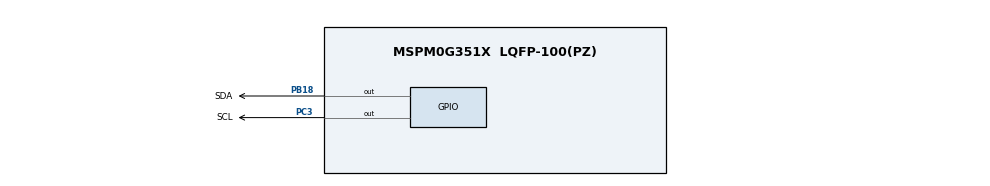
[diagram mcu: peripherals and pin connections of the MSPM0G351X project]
/**
 * @cliArgs --device "MSPM0G351X" --part "Default" --package "LQFP-100(PZ)" --product "mspm0_sdk@2.10.00.04"
 * @versions {"tool":"1.27.0+4565"}
 */

/**
 * Import the modules used in this configuration.
 */
const GPIO    = scripting.addModule("/ti/driverlib/GPIO", {}, false);
const GPIO1   = GPIO.addInstance();
const SYSCTL  = scripting.addModule("/ti/driverlib/SYSCTL");
const SYSTICK = scripting.addModule("/ti/driverlib/SYSTICK");
const UART    = scripting.addModule("/ti/driverlib/UART", {}, false);
const UART1   = UART.addInstance();

/**
 * Write custom configuration values to the imported modules.
 */
const divider9       = system.clockTree["UDIV"];
divider9.divideValue = 2;

const multiplier2         = system.clockTree["PLL_QDIV"];
multiplier2.multiplyValue = 4;

const mux4       = system.clockTree["EXHFMUX"];
mux4.inputSelect = "EXHFMUX_XTAL";

const mux8       = system.clockTree["HSCLKMUX"];
mux8.inputSelect = "HSCLKMUX_SYSPLL0";

const mux12       = system.clockTree["SYSPLLMUX"];
mux12.inputSelect = "zSYSPLLMUX_HFCLK";

const pinFunction4       = system.clockTree["HFXT"];
pinFunction4.inputFreq   = 40;
pinFunction4.enable      = true;
pinFunction4.HFXTStartup = 10;

GPIO1.$name                              = "GPIO_SI5351";
GPIO1.associatedPins.create(2);
GPIO1.associatedPins[0].$name            = "SCL";
GPIO1.associatedPins[0].ioStructure      = "SD";
GPIO1.associatedPins[0].internalResistor = "PULL_UP";
GPIO1.associatedPins[0].initialValue     = "SET";
GPIO1.associatedPins[0].pin.$assign      = "PC3";
GPIO1.associatedPins[1].$name            = "SDA";
GPIO1.associatedPins[1].ioStructure      = "SD";
GPIO1.associatedPins[1].initialValue     = "SET";
GPIO1.associatedPins[1].internalResistor = "PULL_UP";
GPIO1.associatedPins[1].pin.$assign      = "PB18";

const Board = scripting.addModule("/ti/driverlib/Board", {}, false);

SYSCTL.forceDefaultClkConfig = true;
SYSCTL.clockTreeEn           = true;
SYSCTL.validateClkStatus     = true;

SYSTICK.periodEnable  = true;
SYSTICK.systickEnable = true;
SYSTICK.period        = 80000;

UART1.$name                       = "UART_0";
UART1.enableFIFO                  = true;
UART1.rxFifoThreshold             = "DL_UART_RX_FIFO_LEVEL_ONE_ENTRY";
UART1.enabledDMARXTriggers        = "DL_UART_DMA_INTERRUPT_RX";
UART1.txPinConfig.$name           = "ti_driverlib_gpio_GPIOPinGeneric0";
UART1.rxPinConfig.$name           = "ti_driverlib_gpio_GPIOPinGeneric1";
UART1.DMA_CHANNEL_RX.$name        = "DMA_CH0";
UART1.DMA_CHANNEL_RX.srcLength    = "BYTE";
UART1.DMA_CHANNEL_RX.dstLength    = "BYTE";
UART1.DMA_CHANNEL_RX.transferMode = "FULL_CH_REPEAT_SINGLE";

/**
 * Pinmux solution for unlocked pins/peripherals. This ensures that minor changes to the automatic solver in a future
 * version of the tool will not impact the pinmux you originally saw.  These lines can be completely deleted in order to
 * re-solve from scratch.
 */
pinFunction4.peripheral.$suggestSolution           = "SYSCTL";
pinFunction4.peripheral.hfxInPin.$suggestSolution  = "PA5";
pinFunction4.peripheral.hfxOutPin.$suggestSolution = "PA6";
Board.peripheral.$suggestSolution                  = "DEBUGSS";
Board.peripheral.swclkPin.$suggestSolution         = "PA20";
Board.peripheral.swdioPin.$suggestSolution         = "PA19";
UART1.peripheral.$suggestSolution                  = "UART0";
UART1.peripheral.rxPin.$suggestSolution            = "PA1";
UART1.peripheral.txPin.$suggestSolution            = "PA0";
UART1.DMA_CHANNEL_RX.peripheral.$suggestSolution   = "DMA_CH0";
